# LKS32MC07x register map
Vendor: Linko Ltd.; Series: LKS32MC07x; File version: 1.0
CPU: CM0 r1p0, little endian, MPU, no FPU, 3 interrupt priority bits
Registers are 32-bit, read-write, reset 0x0 unless marked. A register's access mark holds for its fields unless they carry their own. Offsets are from the block's base; [hi:lo] are bit positions.

## SPI0 — SPI0 registers
Base 0x40010000
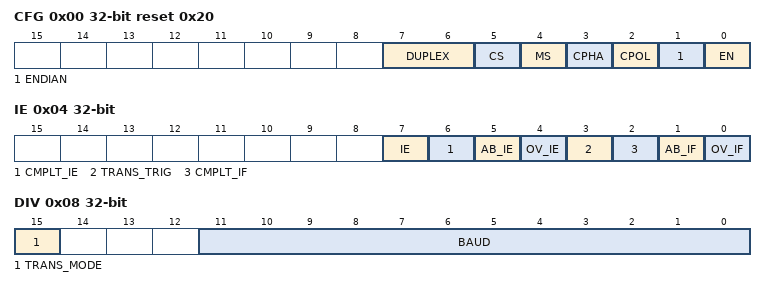
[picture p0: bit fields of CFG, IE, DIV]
0x00 CFG reset 0x20 — SPI Control Register
  [7:6] DUPLEX — Half duplex config
    3=DuplexRx (Duplex with Rx only); 2=DuplexTx (Duplex with Tx only); 0=NoDuplex
  [5] CS — spi chip select control big
    0=Zero (if in spi slave mode, always selected); 1=FromMaster (if in spi slave mode, SPI_CS signal is from spi master)
  [4] MS — spi device is master or slave
    0=slave mode; 1=master mode
  [3] CPHA — spi sample time control bit
    0=LOW (positive clock edge sample data, negative clock edge send data); 1=HIGH (positive clock edge send data, negative clock edge sample data)
  [2] CPOL — clock polarity control bit
    0=LOW (clock default value is low); 1=HIGH (clock default value is high)
  [1] ENDIAN — spi data endian control bit
    0=MSB (big endian mode, most significant bit sent first); 1=LSB (little endian mode, least significant bit sent first)
  [0] EN — spi enable control bit
    0=DISABLED (disable spi module); 1=ENABLED (enable spi module)
0x04 IE — SPI Interrupt Enable
  [7] IE — Interrupt Enable
    0=DISABLED (SPI interrupt is disabled); 1=ENABLED (SPI interrupt is enabled)
  [6] CMPLT_IE — Transfer Complete Interrupt Enable
    0=DISABLED (SPI transfer complete interrupt is disabled); 1=ENABLED (SPI transfer complete interrupt is enabled)
  [5] AB_IE — Abnormal Interrupt Enable
    0=DISABLED (SPI abnormal interrupt is disabled); 1=ENABLED (SPI abnormal interrupt is enabled)
  [4] OV_IE — Overflow Interrupt Enable
    0=DISABLED (SPI overflow interrupt is disabled); 1=ENABLED (SPI overflow interrupt is enabled)
  [3] TRANS_TRIG — Trigger Source
    0=INT (Trigger comes from internal source. Only active in master mode); 1=EXT (Trigger comes from external source)
  [2] CMPLT_IF — Transfer Complete Interrupt
    0=CLEAR (SPI transfer complete interrupt is cleared); 1=SET (SPI transfer complete interrupt is set)
  [1] AB_IF — Abnormal Interrupt
    0=CLEAR (SPI abnormal interrupt is cleared); 1=SET (SPI abnormal interrupt is set)
  [0] OV_IF — Overflow Interrupt
    0=CLEAR (SPI overflow interrupt is cleared); 1=SET (SPI overflow interrupt is set)
0x08 DIV — SPI Clock Division
  [15] TRANS_MODE — by DMA or CPU
    0=DMA (Transfer by DMA); 1=CPU (Transfer by CPU)
  [11:0] BAUD — SPI baudrate = sys_clk/(2*BAUD+1) BAUD should be larger than 3
0x0C TX_DATA — SPI Tx Data
  [15:0] TX_DATA
0x10 RX_DATA — SPI Rx Data
  [15:0] RX_DATA
0x14 SIZE — SPI Transfer size in bits
  [4:0] BITSIZE

## I2C0 — I2C0 registers
Base 0x40010100
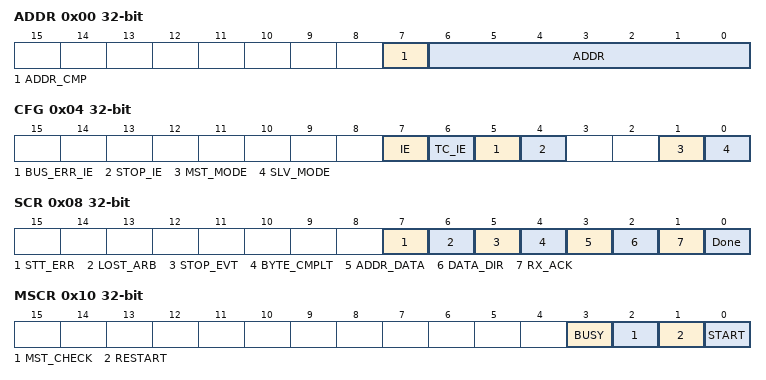
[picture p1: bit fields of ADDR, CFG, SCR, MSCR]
0x00 ADDR — I2C Device Address
  [7] ADDR_CMP — i2c address compared by hardware control bit
    0=DISABLED (disable address compare by hardware); 1=ENABLED (enable address compare by hardware)
  [6:0] ADDR — i2c device address
0x04 CFG — I2C Configuration
  [7] IE — i2c interrupt enable
    0=DISABLED (I2C interrupt is disabled); 1=ENABLED (I2C interrupt is enabled)
  [6] TC_IE — i2c transfer complete interrupt enable
    0=DISABLED (I2C transfer complete interrupt is disabled); 1=ENABLED (I2C transfer complete interrupt is enabled)
  [5] BUS_ERR_IE — i2c bus error interrupt control bit
    0=DISABLED (I2C bus error interrupt disable); 1=ENABLED (I2C bus error interrupt enable.only valid in master mode, master will release bus to idle state)
  [4] STOP_IE — i2c bus error interrupt control bit
    0=DISABLED (I2C stop interrupt is disabled); 1=ENABLED (I2C stop interrupt is enabled)
  [1] MST_MODE — i2c master mode control bit
    0=DISABLED (I2C master mode is disabled); 1=ENABLED (I2C master mode is enabled)
  [0] SLV_MODE — i2c slave mode control bit
    0=DISABLED (I2C slave mode is disabled); 1=ENABLED (I2C slave mode is enabled)
0x08 SCR — I2C State_Control
  [7] STT_ERR — i2c master mode, check out error start/stop.read out 1 means error start/stop happened, write 0 to clear
  [6] LOST_ARB ro — i2c master mode, lost control of bus.i2c master mode, lost control of bus,set this bit to 1.write 0 to clear
  [5] STOP_EVT — i2c stop event happened.read out 1 means stop event happened, write 0 to clear
  [4] BYTE_CMPLT — receive mode, receive done, send ack/nack.receive done, this bit is set to 1 to send ack;set to 0 to send nack.
  [3] ADDR_DATA — addr/data.receive is address data, set to 1; data set to 0. write 0 to clear
  [2] DATA_DIR — send/receive mode select
    0=RX (receive mode); 1=TX (send mode)
  [1] RX_ACK — send mode, sent done, receive ack/nack. send done. receive ack,this bit is set to 1; nack, this bit is set to 0.write 0 to clear
  [0] Done ro — transmit done.current transmit done, set this bit to 1.write 0 to clear
0x0C DATA — I2C Data Regsiter
  [7:0] DATA — i2c data.send mode, write; receive mode, read
0x10 MSCR — I2C Master State_Control
  [3] BUSY ro — i2c busy/idle.bust start, set to 1; bus stop, set to 0
  [2] MST_CHECK ro — i2c device master mode feedback.i2c sends start, set this bit to 1, sends stop set this bit to 0.
  [1] RESTART — i2c generates restart signal.write 1 to generates restart signal, self clear.read out current state
  [0] START — i2c generates start signal.write 1 to generates start signal, self clear..read out current state
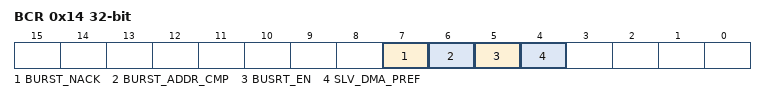
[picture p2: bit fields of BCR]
0x14 BCR — I2C Burst Control
  [7] BURST_NACK — send mode, handle nack
    0=DISABLED (master is in send mode, return to stop. slave is in send mode, return to ilde); 1=ENABLED (generates nack interrupt, pulldown i2c clock bus.)
  [6] BURST_ADDR_CMP — address cmp by hardware, generate interrupt or not
    0=DISABLED (disable address compare by hardware in burst mode); 1=ENABLED (enable address compare by hardware in burst mode)
  [5] BUSRT_EN — Burst Mode Control Bit
    0=DISABLED (disable burst mode); 1=ENABLED (enable burst mode)
  [4] SLV_DMA_PREF — Slave DMA prefetch enable
    0=DISABLED (disable slave prefetch); 1=ENABLED (enable slave prefetch)
0x18 BSIZE — I2C Transfer byte size
  [4:0] SIZE
